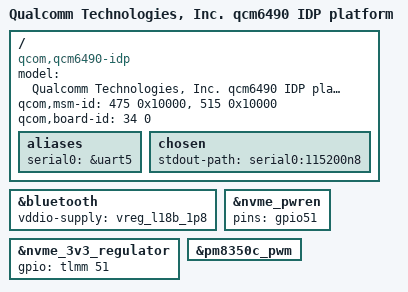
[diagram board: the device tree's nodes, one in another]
// SPDX-License-Identifier: BSD-3-Clause
/*
 * qcm6490 IDP device tree source
 *
 * Copyright (c) 2023 Qualcomm Innovation Center, Inc. All rights reserved.
 *
 */

/dts-v1/;

#include "sc7280-idp.dtsi"

/ {
	model = "Qualcomm Technologies, Inc. qcm6490 IDP platform";
	compatible = "qcom,qcm6490-idp","qcom,sc7280";
	qcom,msm-id = <475 0x10000>, <515 0x10000>;
	qcom,board-id = <34 0>;

	aliases {
		serial0 = &uart5;
	};

	chosen {
		stdout-path = "serial0:115200n8";
	};
};

&bluetooth {
	vddio-supply = <&vreg_l18b_1p8>;
};

&nvme_pwren {
	pins = "gpio51";
};

&nvme_3v3_regulator {
	gpio = <&tlmm 51 GPIO_ACTIVE_HIGH>;
};

&pm8350c_pwm {
	status = "okay";
};
